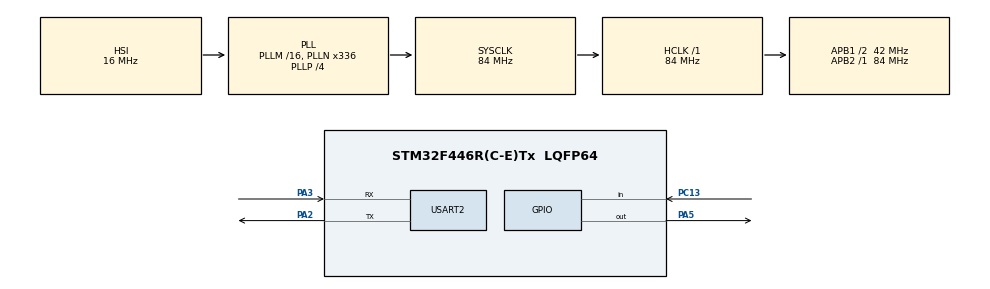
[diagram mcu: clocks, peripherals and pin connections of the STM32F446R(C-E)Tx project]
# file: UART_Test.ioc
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Dma.Request0=USART2_RX
Dma.USART2_RX.0.Direction=DMA_PERIPH_TO_MEMORY
Dma.USART2_RX.0.FIFOMode=DMA_FIFOMODE_DISABLE
Dma.USART2_RX.0.Instance=DMA1_Stream5
Dma.USART2_RX.0.MemDataAlignment=DMA_MDATAALIGN_BYTE
Dma.USART2_RX.0.MemInc=DMA_MINC_ENABLE
Dma.USART2_RX.0.Mode=DMA_NORMAL
Dma.USART2_RX.0.PeriphDataAlignment=DMA_PDATAALIGN_BYTE
Dma.USART2_RX.0.PeriphInc=DMA_PINC_DISABLE
Dma.USART2_RX.0.Priority=DMA_PRIORITY_LOW
Mcu.Family=STM32F4
Mcu.Name=STM32F446R(C-E)Tx
Mcu.Package=LQFP64
NVIC.DMA1_Stream5_IRQn=true\:0\:0\:false\:false\:true\:false\:true
NVIC.PriorityGroup=NVIC_PRIORITYGROUP_0
NVIC.USART2_IRQn=true\:0\:0\:false\:false\:true\:true\:true
PA2.Mode=Asynchronous
PA2.Signal=USART2_TX
PA3.Mode=Asynchronous
PA3.Signal=USART2_RX
PA5.Signal=GPIO_Output
PC13.Signal=GPIO_Input
ProjectManager.HeapSize=0x200
ProjectManager.StackSize=0x400
ProjectManager.TargetToolchain=STM32CubeIDE
RCC.48MHZClocksFreq_Value=84000000
RCC.AHBFreq_Value=84000000
RCC.APB1CLKDivider=RCC_HCLK_DIV2
RCC.APB1Freq_Value=42000000
RCC.APB1TimFreq_Value=84000000
RCC.APB2Freq_Value=84000000
RCC.APB2TimFreq_Value=84000000
RCC.CortexFreq_Value=84000000
RCC.FLatency-AdvancedSettings=FLASH_LATENCY_2
RCC.HCLKFreq_Value=84000000
RCC.HSE_VALUE=8000000
RCC.HSI_VALUE=16000000
RCC.PLLN=336
RCC.PLLP=RCC_PLLP_DIV4
RCC.SYSCLKFreq_VALUE=84000000
RCC.SYSCLKSource=RCC_SYSCLKSOURCE_PLLCLK
RCC.USBFreq_Value=168000000
RCC.VCOOutputFreq_Value=336000000
USART2.VirtualMode=VM_ASYNC
board=NUCLEO-F446RE

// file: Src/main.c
/* USER CODE BEGIN Header */
/**
  ******************************************************************************
  * @file           : main.c
  * @brief          : Main program body
  ******************************************************************************
  * @attention
  *
  * <h2><center>&copy; Copyright (c) 2020 STMicroelectronics.
  * All rights reserved.</center></h2>
  *
  * This software component is licensed by ST under BSD 3-Clause license,
  * the "License"; You may not use this file except in compliance with the
  * License. You may obtain a copy of the License at:
  *                        opensource.org/licenses/BSD-3-Clause
  *
  ******************************************************************************
  */
/* USER CODE END Header */

#include "main.h"
#include "dma.h"
#include "usart.h"
#include "gpio.h"
#include "stm32f4xx_hal.h"
#include "stm32f4xx_hal_uart.h"

UART_HandleTypeDef huart2;
DMA_HandleTypeDef hdma_usart2_rx;

void SystemClock_Config(void);

/* USER CODE BEGIN 0 */
uint8_t myTxData[13]= "Hello World\r\n";
uint8_t myRxData[11];
/* USER CODE END 0 */

int main(void)
{

  /* MCU Configuration--------------------------------------------------------*/

  /* Reset of all peripherals, Initializes the Flash interface and the Systick. */
  HAL_Init();

  /* Configure the system clock */
  SystemClock_Config();

  /* Initialize all configured peripherals */
  MX_GPIO_Init();
  MX_USART2_UART_Init();
  MX_DMA_Init();
  /* USER CODE BEGIN 2 */
  HAL_UART_Receive_IT(&huart2, myRxData, 11);
 //define UART callback,when we receive the full 11 bytes it will interrupt and I can read them
  /* USER CODE END 2 */

  /* Infinite loop */
  while (1)
  {
	 //HAL_UART_Transmit(&huart2, myTxData, 13, 10);//datasize=13;10ms enough
	  HAL_GPIO_TogglePin(GPIOA, GPIO_PIN_5);

	  HAL_Delay(1000);
  }
}

void SystemClock_Config(void)
{
  RCC_OscInitTypeDef RCC_OscInitStruct = {0};
  RCC_ClkInitTypeDef RCC_ClkInitStruct = {0};

  /** Configure the main internal regulator output voltage
  */
  __HAL_RCC_PWR_CLK_ENABLE();
  __HAL_PWR_VOLTAGESCALING_CONFIG(PWR_REGULATOR_VOLTAGE_SCALE3);
  /** Initializes the CPU, AHB and APB busses clocks
  */
  RCC_OscInitStruct.OscillatorType = RCC_OSCILLATORTYPE_HSI;
  RCC_OscInitStruct.HSIState = RCC_HSI_ON;
  RCC_OscInitStruct.HSICalibrationValue = RCC_HSICALIBRATION_DEFAULT;
  RCC_OscInitStruct.PLL.PLLState = RCC_PLL_ON;
  RCC_OscInitStruct.PLL.PLLSource = RCC_PLLSOURCE_HSI;
  RCC_OscInitStruct.PLL.PLLM = 16;
  RCC_OscInitStruct.PLL.PLLN = 336;
  RCC_OscInitStruct.PLL.PLLP = RCC_PLLP_DIV4;
  RCC_OscInitStruct.PLL.PLLQ = 2;
  RCC_OscInitStruct.PLL.PLLR = 2;
  if (HAL_RCC_OscConfig(&RCC_OscInitStruct) != HAL_OK)
  {
    Error_Handler();
  }
  /** Initializes the CPU, AHB and APB busses clocks
  */
  RCC_ClkInitStruct.ClockType = RCC_CLOCKTYPE_HCLK|RCC_CLOCKTYPE_SYSCLK
                              |RCC_CLOCKTYPE_PCLK1|RCC_CLOCKTYPE_PCLK2;
  RCC_ClkInitStruct.SYSCLKSource = RCC_SYSCLKSOURCE_PLLCLK;
  RCC_ClkInitStruct.AHBCLKDivider = RCC_SYSCLK_DIV1;
  RCC_ClkInitStruct.APB1CLKDivider = RCC_HCLK_DIV2;
  RCC_ClkInitStruct.APB2CLKDivider = RCC_HCLK_DIV1;

  if (HAL_RCC_ClockConfig(&RCC_ClkInitStruct, FLASH_LATENCY_2) != HAL_OK)
  {
    Error_Handler();
  }
}

/* USER CODE BEGIN 4 */
void HAL_UART_RxCpltCallback(UART_HandleTypeDef *huart)
{
  /* Prevent unused argument(s) compilation warning */
  UNUSED(huart);
  /* NOTE: This function should not be modified, when the callback is needed,
           the HAL_UART_RxCpltCallback could be implemented in the user file
   */
  HAL_UART_Transmit(&huart2, myRxData, 11, 10);
}
/* USER CODE END 4 */

void Error_Handler(void)
{
}

/************************ (C) COPYRIGHT STMicroelectronics *****END OF FILE****/
